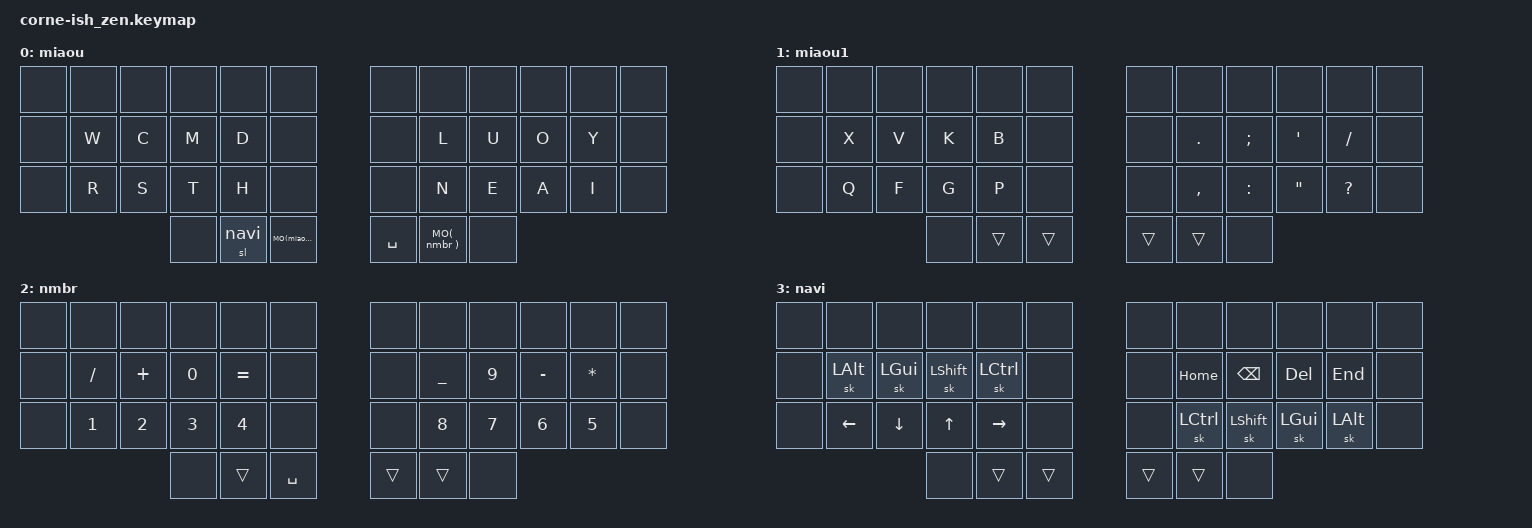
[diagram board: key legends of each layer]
/*
*
* Copyright (c) 2021 lowprokb.ca
* SPDX-License-Identifier: MIT
*
*/

#include <behaviors.dtsi>
#include <dt-bindings/zmk/keys.h>
#include <dt-bindings/zmk/bt.h>
#include "ciz.h"

#define miaou  0
#define miaou1 1
#define  nmbr  2
#define  navi  3

&caps_word {
    continue-list = <UNDERSCORE MINUS>;
};

&sk {
  release-after-ms = <STICKY_KEY_TIMEOUT>;
};

/ {
  combos {
    #include "combos.dtsi"
  };

  behaviors {
    skq: sticky_key_quick_release {
    compatible = "zmk,behavior-sticky-key";
    label = "STICKY_KEY_QUICK_RELEASE";
    #binding-cells = <1>;
    bindings = <&kp>;
    quick-release;
    release-after-ms = <STICKY_KEY_TIMEOUT>;
  };

  // Use hold-tap to enable rolling sticky keys:
  // https://github.com/zmkfirmware/zmk/issues/829#issuecomment-979864774
  nk: not_so_sticky_key {
    compatible = "zmk,behavior-hold-tap";
    label = "NOT_SO_STICKY_KEY";
    #binding-cells = <2>;
    tapping_term_ms = <200>;
    flavor = "tap-preferred";
    bindings = <&kp>, <&sk>;
  };

  // A hold-tap that activates without delay (like `&mo`)
  mo_tap: mo_with_tap {
    compatible = "zmk,behavior-hold-tap";
    label = "MO_WITH_TAP";
    #binding-cells = <2>;
    tapping_term_ms = <0>;
    retro-tap;
    flavor = "hold-preferred";
    bindings = <&mo>, <&kp>;
  };
};
        keymap {
                compatible = "zmk,keymap";
                              
                miaou_layer {
                        label = "miaou ";
                        bindings = <
                &none   &none &none &none &none &none                   &none &none &none &none &none                   &none
                &none   &kp W &kp C &kp M &kp D &none                   &none &kp L &kp U &kp O &kp Y                   &none
                &none   &kp R &kp S &kp T &kp H &none                   &none &kp N &kp E &kp A &kp I                   &none
                                &none &sl  navi  MO(miaou1)                     &kp SPACE MO( nmbr ) &none
                        >;
                };
                
                miaou1_layer {
                        label = "miaou1";
                        bindings = <
                &none   &none &none &none &none &none                   &none &none &none &none &none                   &none
                &none   &kp X &kp V &kp K &kp B &none                   &none &kp DOT   &kp SEMI  &kp SQT &kp FSLH      &none
                &none   &kp Q &kp F &kp G &kp P &none                   &none &kp COMMA &kp COLON &kp DQT &kp QMARK     &none
                                &none &trans &trans                             &trans &trans &none
                        >;
                };
                
                nmbr_layer {
                        label = " nmbr ";
                        bindings = <
                &none   &none &none &none &none &none                   &none &none &none &none &none                   &none
                &none   &kp FSLH &kp PLUS &kp N0 &kp EQUAL &none        &none &kp UNDER &kp N9 &kp MINUS &kp STAR       &none
                &none   &kp N1   &kp N2   &kp N3 &kp N4    &none        &none &kp N8    &kp N7 &kp N6    &kp N5         &none
                                   &none &trans &kp SPACE                       &trans &trans &none
                        >;
                };
                
                navi_layer {
                        label = " navi ";
                        bindings = <
                &none   &none &none &none &none &none                   &none &none &none &none &none                   &none
                &none   &sk LALT &sk LGUI &sk LSHFT &sk LCTL  &none     &none &kp HOME &kp BSPC  &kp DEL  &kp END       &none
                &none   &kp LEFT &kp DOWN &kp UP    &kp RIGHT &none     &none &sk LCTL &sk LSHFT &sk LGUI &sk LALT      &none
                                   &none &trans &trans                          &trans &trans &none
                        >;
                };
        };
};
